VERSION ""

NS_ :

BS_:
BU_: USB2CANA CANABLE
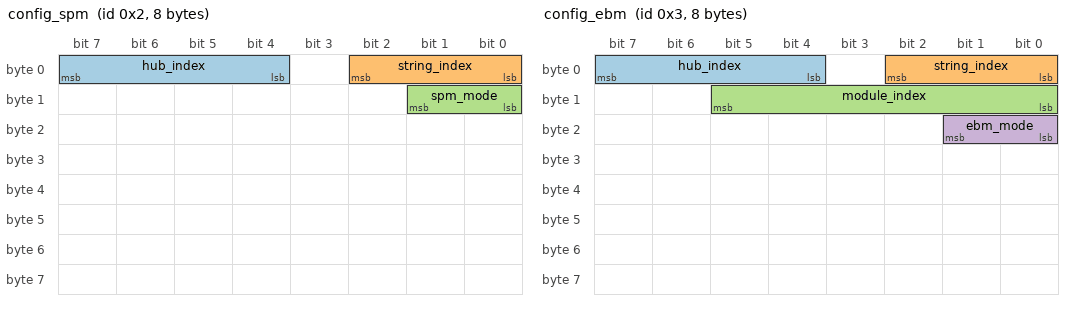
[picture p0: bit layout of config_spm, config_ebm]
BO_ 2 config_spm: 8 USB2CANA
   SG_ hub_index : 4|4@1+ (1,0) [0|1] "" Vector__XXX
   SG_ string_index : 0|3@1+ (1,0) [0|1] "" CANABLE
   SG_ spm_mode : 8|2@1+ (1,0) [0|2] "" Vector__XXX

BO_ 3 config_ebm: 8 USB2CANA
   SG_ hub_index : 4|4@1+ (1,0) [0|15] "" Vector__XXX
   SG_ string_index : 0|3@1+ (1,0) [0|7] "" Vector__XXX
   SG_ module_index : 8|6@1+ (1,0) [0|63] "" Vector__XXX
   SG_ ebm_mode : 16|2@1+ (1,0) [0|3] "" Vector__XXX

BO_ 4 test_multiplexing: 8 USB2CANA
   SG_ sample_multiplexor_0 M : 0|2@1+ (1,0) [0|3] "" Vector__XXX
   SG_ sample_multiplexed_0 m0 : 8|8@1+ (1,0) [0|15] "" Vector__XXX
   SG_ sample_multiplexor_2 M : 0|2@1+ (1,0) [0|3] "" Vector__XXX
   SG_ sample_multiplexed_1 m1 : 8|8@1+ (1,0) [0|15] "" Vector__XXX

CM_ BU_ USB2CANA "Waveshare USB-CAN-A";
CM_ BU_ CANABLE "MKS CANable V2.0 Pro";
CM_ BO_ 4 "verify DBC multiplexing";
BA_DEF_ BO_ "GenMsgBackgroundColor" STRING ;
BA_DEF_ BO_ "GenMsgForegroundColor" STRING ;
BA_DEF_ BO_ "filterlabeling" INT 0 0;
BA_DEF_ BO_ "filterlabeling" INT 0 0;
BA_DEF_ BO_ "filterlabeling" INT 0 0;
BA_DEF_ BO_ "filterlabeling" INT 0 0;
BA_DEF_DEF_ "GenMsgBackgroundColor" "#ffffff";
BA_DEF_DEF_ "GenMsgForegroundColor" "#000000";
BA_DEF_DEF_ "filterlabeling" 1;
BA_DEF_DEF_ "filterlabeling" 1;
VAL_ 2 spm_mode 0 "SPM_Disconnect_Mode" 1 "SPM_Resistor_Mode_(0x1)" 2 "SPM_Resistor_Mode_(0x2)";
VAL_ 3 ebm_mode 0 "EBM_Disconnect_Mode" 1 "EBM_Enable_Mode" 3 "EBM_Bypass_Mode";
VAL_ 4 sample_multiplexor_0 0 "the_first_multiplexed_signal_value" 1 "the_second_multiplexed_signal_value" 2 "the_third_multiplexed_signal_value" 3 "the_fourth_multplexed_signal_value";
VAL_ 4 sample_multiplexed_0 0 "the_first_multiplexed_signal_value" 1 "the_second_multiplexed_signal_value" 2 "the_third_multiplexed_signal_value" 3 "the_fourth_multiplexed_signal_value";
VAL_ 4 sample_multiplexor_2 0 "the_first_multiplexed_signal_value" 1 "the_second_multiplexed_signal_value" 2 "the_third_multiplexed_signal_value" 3 "the_fourth_multplexed_signal_value";
VAL_ 4 sample_multiplexed_1 0 "the_first_multiplexed_signal_value" 1 "the_second_multiplexed_signal_value" 2 "the_third_multiplexed_signal_value" 3 "the_fourth_multiplexed_signal_value";
